AUTOSAR XML (schema 4-0-3)
standard types defined: Boolean, UInt16, UInt32, UInt8
package /AUTOSAR_Platform/DataConstrs
  range DC_Boolean: raw 0..1
  range DC_UInt16: raw 0..65535
  range DC_UInt8: raw 0..255
package /PATAC/MSM/ComponentTypes
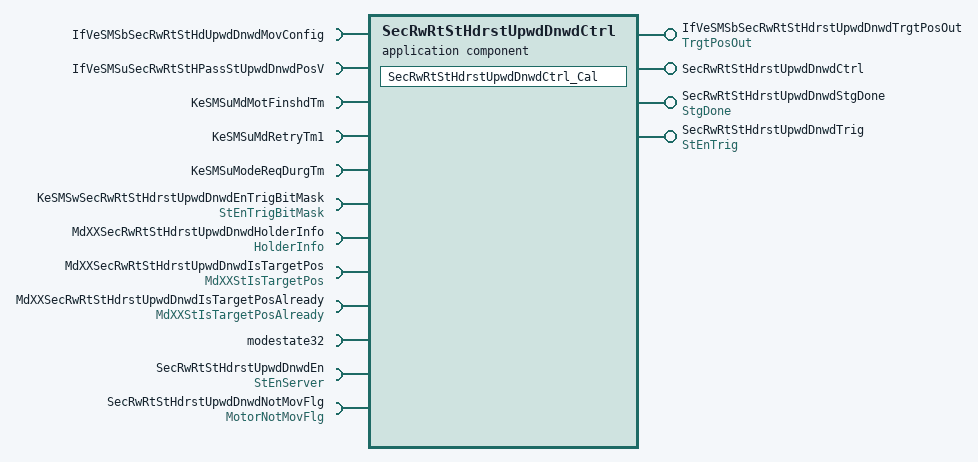
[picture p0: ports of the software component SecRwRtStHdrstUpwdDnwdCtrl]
  application sw component type SecRwRtStHdrstUpwdDnwdCtrl
    4 x provide port:
      IfVeSMSbSecRwRtStHdrstUpwdDnwdTrgtPosOut: nonqueued-sender-com-spec{data-element=TrgtPosOut/Val, init-value=0}, provided-interface=TrgtPosOut
      SecRwRtStHdrstUpwdDnwdCtrl: server-com-spec{operation=Cal, queue-length=1}, provided-interface=SecRwRtStHdrstUpwdDnwdCtrl
      SecRwRtStHdrstUpwdDnwdStgDone: nonqueued-sender-com-spec{data-element=StgDone/Val, init-value=0}, provided-interface=StgDone
      SecRwRtStHdrstUpwdDnwdTrig: nonqueued-sender-com-spec{data-element=StEnTrig/Val, init-value=0}, provided-interface=StEnTrig
    12 x require port:
      IfVeSMSbSecRwRtStHdUpwdDnwdMovConfig: nonqueued-receiver-com-spec{data-element=IfVeSMSbSecRwRtStHdUpwdDnwdMovConfig/Val, filter=data-filter-type=ALWAYS, init-value=0}, required-interface=IfVeSMSbSecRwRtStHdUpwdDnwdMovConfig
      IfVeSMSuSecRwRtStHPassStUpwdDnwdPosV: nonqueued-receiver-com-spec{data-element=IfVeSMSuSecRwRtStHPassStUpwdDnwdPosV/Val, filter=data-filter-type=ALWAYS, init-value=0}, required-interface=IfVeSMSuSecRwRtStHPassStUpwdDnwdPosV
      KeSMSuMdMotFinshdTm: parameter-require-com-spec{init-value=0, parameter=KeSMSuMdMotFinshdTm/Val}, required-interface=KeSMSuMdMotFinshdTm
      KeSMSuMdRetryTm1: parameter-require-com-spec{init-value=0, parameter=KeSMSuMdRetryTm1/Val}, required-interface=KeSMSuMdRetryTm1
      KeSMSuModeReqDurgTm: parameter-require-com-spec{init-value=0, parameter=KeSMSuModeReqDurgTm/Val}, required-interface=KeSMSuModeReqDurgTm
      KeSMSwSecRwRtStHdrstUpwdDnwdEnTrigBitMask: parameter-require-com-spec{init-value=6153, parameter=StEnTrigBitMask/Val}, required-interface=StEnTrigBitMask
      MdXXSecRwRtStHdrstUpwdDnwdHolderInfo: nonqueued-receiver-com-spec{data-element=HolderInfo/Val, filter=data-filter-type=ALWAYS, init-value=0}, required-interface=HolderInfo
      MdXXSecRwRtStHdrstUpwdDnwdIsTargetPos: nonqueued-receiver-com-spec{data-element=MdXXStIsTargetPos/Val, filter=data-filter-type=ALWAYS, init-value=0}, required-interface=MdXXStIsTargetPos
      MdXXSecRwRtStHdrstUpwdDnwdIsTargetPosAlready: nonqueued-receiver-com-spec{data-element=MdXXStIsTargetPosAlready/Val, filter=data-filter-type=ALWAYS, init-value=0}, required-interface=MdXXStIsTargetPosAlready
      modestate32: nonqueued-receiver-com-spec{data-element=modestate32/Val, filter=data-filter-type=ALWAYS, init-value=0}, required-interface=modestate32
      SecRwRtStHdrstUpwdDnwdEn: required-com-specs=[Clear, Get, Set], required-interface=StEnServer
      SecRwRtStHdrstUpwdDnwdNotMovFlg: nonqueued-receiver-com-spec{data-element=MotorNotMovFlg/Val, filter=data-filter-type=ALWAYS, init-value=0}, required-interface=MotorNotMovFlg
    behavior SecRwRtStHdrstUpwdDnwdCtrl_InternalBehavior
      operation invoked event OIT_SecRwRtStHdrstUpwdDnwdCtrl_Cal_SecRwRtStHdrstUpwdDnwdCtrl_Cal: start-on-event=SecRwRtStHdrstUpwdDnwdCtrl_Cal, operation=SecRwRtStHdrstUpwdDnwdCtrl.Cal
      runnable SecRwRtStHdrstUpwdDnwdCtrl_Cal
        data-receive-point-by-arguments:
          7 x access:
            REC_IfVeSMSbSecRwRtStHdUpwdDnwdMovConfig_Val: accessed-variable=IfVeSMSbSecRwRtStHdUpwdDnwdMovConfig.Val
            REC_IfVeSMSuSecRwRtStHPassStUpwdDnwdPosV_Val: accessed-variable=IfVeSMSuSecRwRtStHPassStUpwdDnwdPosV.Val
            REC_MdXXSecRwRtStHdrstUpwdDnwdHolderInfo_Val: accessed-variable=MdXXSecRwRtStHdrstUpwdDnwdHolderInfo.Val
            REC_MdXXSecRwRtStHdrstUpwdDnwdIsTargetPos_Val: accessed-variable=MdXXSecRwRtStHdrstUpwdDnwdIsTargetPos.Val
            REC_MdXXSecRwRtStHdrstUpwdDnwdIsTargetPosAlready_Val: accessed-variable=MdXXSecRwRtStHdrstUpwdDnwdIsTargetPosAlready.Val
            REC_modestate32_Val: accessed-variable=modestate32.Val
            REC_SecRwRtStHdrstUpwdDnwdNotMovFlg_Val: accessed-variable=SecRwRtStHdrstUpwdDnwdNotMovFlg.Val
        data-send-points:
          access SEND_IfVeSMSbSecRwRtStHdrstUpwdDnwdTrgtPosOut_Val: accessed-variable=IfVeSMSbSecRwRtStHdrstUpwdDnwdTrgtPosOut.Val
          access SEND_SecRwRtStHdrstUpwdDnwdStgDone_Val: accessed-variable=SecRwRtStHdrstUpwdDnwdStgDone.Val
          access SEND_SecRwRtStHdrstUpwdDnwdTrig_Val: accessed-variable=SecRwRtStHdrstUpwdDnwdTrig.Val
        4 x parameter access:
          PA_KeSMSuMdMotFinshdTm_Val: accessed-parameter=KeSMSuMdMotFinshdTm.Val
          PA_KeSMSuMdRetryTm1_Val: accessed-parameter=KeSMSuMdRetryTm1.Val
          PA_KeSMSuModeReqDurgTm_Val: accessed-parameter=KeSMSuModeReqDurgTm.Val
          PA_KeSMSwSecRwRtStHdrstUpwdDnwdEnTrigBitMask_Val: accessed-parameter=KeSMSwSecRwRtStHdrstUpwdDnwdEnTrigBitMask.Val
        sync call SC_SecRwRtStHdrstUpwdDnwdEn_Get: operation=SecRwRtStHdrstUpwdDnwdEn.Get, timeout=0
  swc implementation SecRwRtStHdrstUpwdDnwdCtrl_Implementation: behavior=SecRwRtStHdrstUpwdDnwdCtrl_InternalBehavior
    code-descriptors:
      code Default: artifact-descriptors=autosar-engineering-object={short-label=Default, category=SWSRC}
package /PATAC/MSM/ModeAdjust/CalPortInterface
  parameter interface KeSMSuMdMotFinshdTm
    parameter data prototype Val: sw-calibration-access=READ-WRITE, type=UInt16
  parameter interface KeSMSuModeReqDurgTm
    parameter data prototype Val: sw-calibration-access=READ-WRITE, type=UInt16
  parameter interface StEnTrigBitMask
    parameter data prototype Val: sw-calibration-access=READ-WRITE, type=UInt32
package /PATAC/MSM/ModeAdjust/Interfaces
  sender receiver interface IfVeSMSuSecRwRtStHPassStUpwdDnwdPosV: invalidation-policy{data-element=IfVeSMSuSecRwRtStHPassStUpwdDnwdPosV/Val, handle-invalid=DONT-INVALIDATE}
    data Val: type=Boolean
package /PATAC/MSM/ModeAdjust/PortInterface
  client server interface SecRwRtStHdrstUpwdDnwdCtrl
    operation Cal
  client server interface StEnServer
    operation Clear
      arg data: type=UInt8, direction=IN, server-argument-impl-policy=USE-ARGUMENT-TYPE
    operation Get
      arg data: type=UInt32, direction=OUT, server-argument-impl-policy=USE-ARGUMENT-TYPE
    operation Set
      arg data: type=UInt8, direction=IN, server-argument-impl-policy=USE-ARGUMENT-TYPE
  9 x sender receiver interface:
    HolderInfo: invalidation-policy{data-element=HolderInfo/Val, handle-invalid=DONT-INVALIDATE}
      data Val: type=UInt32
    IfVeSMSbSecRwRtStHdUpwdDnwdMovConfig: invalidation-policy{data-element=IfVeSMSbSecRwRtStHdUpwdDnwdMovConfig/Val, handle-invalid=DONT-INVALIDATE}
      data Val: type=Boolean
    MdXXStIsTargetPos: invalidation-policy{data-element=MdXXStIsTargetPos/Val, handle-invalid=DONT-INVALIDATE}
      data Val: type=UInt32
    MdXXStIsTargetPosAlready: invalidation-policy{data-element=MdXXStIsTargetPosAlready/Val, handle-invalid=DONT-INVALIDATE}
      data Val: type=UInt32
    modestate32: invalidation-policy{data-element=modestate32/Val, handle-invalid=DONT-INVALIDATE}
      data Val: type=UInt32
    MotorNotMovFlg: invalidation-policy{data-element=MotorNotMovFlg/Val, handle-invalid=DONT-INVALIDATE}
      data Val: type=Boolean
    StEnTrig: invalidation-policy{data-element=StEnTrig/Val, handle-invalid=DONT-INVALIDATE}
      data Val: type=Boolean
    StgDone: invalidation-policy{data-element=StgDone/Val, handle-invalid=DONT-INVALIDATE}
      data Val: type=Boolean
    TrgtPosOut: invalidation-policy{data-element=TrgtPosOut/Val, handle-invalid=DONT-INVALIDATE}
      data Val: type=Boolean
package /PATAC/MSM/PortInterfaces
  parameter interface KeSMSuMdRetryTm1
    parameter data prototype Val: sw-calibration-access=READ-WRITE, type=UInt8
